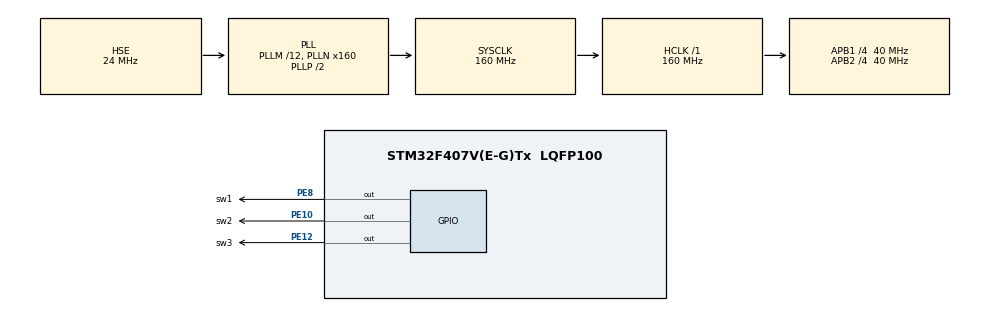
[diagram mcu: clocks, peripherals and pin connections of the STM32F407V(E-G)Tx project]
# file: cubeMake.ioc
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Mcu.Family=STM32F4
Mcu.Name=STM32F407V(E-G)Tx
Mcu.Package=LQFP100
NVIC.PriorityGroup=NVIC_PRIORITYGROUP_4
PE10.GPIO_Label=sw2
PE10.Signal=GPIO_Output
PE12.GPIO_Label=sw3
PE12.Signal=GPIO_Output
PE8.GPIO_Label=sw1
PE8.Signal=GPIO_Output
PH0-OSC_IN.Mode=HSE-External-Oscillator
PH0-OSC_IN.Signal=RCC_OSC_IN
PH1-OSC_OUT.Mode=HSE-External-Oscillator
PH1-OSC_OUT.Signal=RCC_OSC_OUT
ProjectManager.HeapSize=0x200
ProjectManager.StackSize=0x400
ProjectManager.TargetToolchain=Makefile
RCC.48MHZClocksFreq_Value=80000000
RCC.AHBFreq_Value=160000000
RCC.APB1CLKDivider=RCC_HCLK_DIV4
RCC.APB1Freq_Value=40000000
RCC.APB1TimFreq_Value=80000000
RCC.APB2CLKDivider=RCC_HCLK_DIV4
RCC.APB2Freq_Value=40000000
RCC.APB2TimFreq_Value=80000000
RCC.CortexFreq_Value=160000000
RCC.HCLKFreq_Value=160000000
RCC.HSE_VALUE=24000000
RCC.HSI_VALUE=16000000
RCC.LSE_VALUE=32768
RCC.PLLM=12
RCC.PLLN=160
RCC.PLLSourceVirtual=RCC_PLLSOURCE_HSE
RCC.SYSCLKFreq_VALUE=160000000
RCC.SYSCLKSource=RCC_SYSCLKSOURCE_PLLCLK
RCC.VCOOutputFreq_Value=320000000
board=custom

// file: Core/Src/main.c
/* USER CODE BEGIN Header */
/**
  ******************************************************************************
  * @file           : main.c
  * @brief          : Main program body
  ******************************************************************************
  * @attention
  *
  * Copyright (c) 2025 STMicroelectronics.
  * All rights reserved.
  *
  * This software is licensed under terms that can be found in the LICENSE file
  * in the root directory of this software component.
  * If no LICENSE file comes with this software, it is provided AS-IS.
  *
  ******************************************************************************
  */
/* USER CODE END Header */
#include "main.h"
#include "gpio.h"

/* USER CODE BEGIN PTD */
uint32_t counter = 0;
uint32_t seconds = 0;
uint32_t tiks = 0;
uint32_t *VectorTable;
/* USER CODE END PTD */

void SystemClock_Config(void);

int main(void)
{
  // запись вектора прерываний в оперативную память, последний килобайт
  // при использовании необходимо выставить в линковщике правильный размер
  // даташит - 1
  uint32_t BL_PROGRAMM_START_ADRESS = 0x08010008;
  uint32_t MAIN_PROGRAM_RAM_START   = 0x2001BC00;

  uint32_t *VectorTable = (uint32_t *)(MAIN_PROGRAM_RAM_START);
  for (uint8_t i = 0; i < 106; i++)
  {
    VectorTable[i] = *(__IO uint32_t *)(BL_PROGRAMM_START_ADRESS + (i << 2));
  }

  SCB->VTOR = MAIN_PROGRAM_RAM_START;
  __enable_irq();
  /* USER CODE END 1 */

  /* MCU Configuration--------------------------------------------------------*/

  /* Reset of all peripherals, Initializes the Flash interface and the Systick. */
  HAL_Init();

  /* Configure the system clock */
  SystemClock_Config();

  /* Initialize all configured peripherals */
  MX_GPIO_Init();

  /* Infinite loop */
  while (1)
  {
    HAL_GPIO_WritePin(sw1_GPIO_Port, sw1_Pin, GPIO_PIN_SET);
    HAL_GPIO_WritePin(sw2_GPIO_Port, sw2_Pin, GPIO_PIN_RESET);
    HAL_GPIO_WritePin(sw3_GPIO_Port, sw3_Pin, GPIO_PIN_RESET);
	  HAL_Delay(1000);
	  HAL_GPIO_WritePin(sw1_GPIO_Port, sw1_Pin, GPIO_PIN_SET);
    HAL_GPIO_WritePin(sw2_GPIO_Port, sw2_Pin, GPIO_PIN_SET);
    HAL_GPIO_WritePin(sw3_GPIO_Port, sw3_Pin, GPIO_PIN_RESET);
	  HAL_Delay(1000);
    HAL_GPIO_WritePin(sw1_GPIO_Port, sw1_Pin, GPIO_PIN_SET);
    HAL_GPIO_WritePin(sw2_GPIO_Port, sw2_Pin, GPIO_PIN_SET);
    HAL_GPIO_WritePin(sw3_GPIO_Port, sw3_Pin, GPIO_PIN_SET);
	  HAL_Delay(1000);
    HAL_GPIO_WritePin(sw1_GPIO_Port, sw1_Pin, GPIO_PIN_RESET);
    HAL_GPIO_WritePin(sw2_GPIO_Port, sw2_Pin, GPIO_PIN_RESET);
    HAL_GPIO_WritePin(sw3_GPIO_Port, sw3_Pin, GPIO_PIN_RESET);
    counter++;
    HAL_Delay(200);
    tiks = HAL_GetTick();
    seconds = tiks/1000;
  }
}

void SystemClock_Config(void)
{
  RCC_OscInitTypeDef RCC_OscInitStruct = {0};
  RCC_ClkInitTypeDef RCC_ClkInitStruct = {0};

  /** Configure the main internal regulator output voltage
  */
  __HAL_RCC_PWR_CLK_ENABLE();
  __HAL_PWR_VOLTAGESCALING_CONFIG(PWR_REGULATOR_VOLTAGE_SCALE1);

  /** Initializes the RCC Oscillators according to the specified parameters
  * in the RCC_OscInitTypeDef structure.
  */
  RCC_OscInitStruct.OscillatorType = RCC_OSCILLATORTYPE_HSE;
  RCC_OscInitStruct.HSEState = RCC_HSE_ON;
  RCC_OscInitStruct.PLL.PLLState = RCC_PLL_ON;
  RCC_OscInitStruct.PLL.PLLSource = RCC_PLLSOURCE_HSE;
  RCC_OscInitStruct.PLL.PLLM = 12;
  RCC_OscInitStruct.PLL.PLLN = 160;
  RCC_OscInitStruct.PLL.PLLP = RCC_PLLP_DIV2;
  RCC_OscInitStruct.PLL.PLLQ = 4;
  if (HAL_RCC_OscConfig(&RCC_OscInitStruct) != HAL_OK)
  {
    Error_Handler();
  }

  /** Initializes the CPU, AHB and APB buses clocks
  */
  RCC_ClkInitStruct.ClockType = RCC_CLOCKTYPE_HCLK|RCC_CLOCKTYPE_SYSCLK
                              |RCC_CLOCKTYPE_PCLK1|RCC_CLOCKTYPE_PCLK2;
  RCC_ClkInitStruct.SYSCLKSource = RCC_SYSCLKSOURCE_PLLCLK;
  RCC_ClkInitStruct.AHBCLKDivider = RCC_SYSCLK_DIV1;
  RCC_ClkInitStruct.APB1CLKDivider = RCC_HCLK_DIV4;
  RCC_ClkInitStruct.APB2CLKDivider = RCC_HCLK_DIV4;

  if (HAL_RCC_ClockConfig(&RCC_ClkInitStruct, FLASH_LATENCY_5) != HAL_OK)
  {
    Error_Handler();
  }
}

void Error_Handler(void)
{
  __disable_irq();
  while (1)
  {
  }
}
